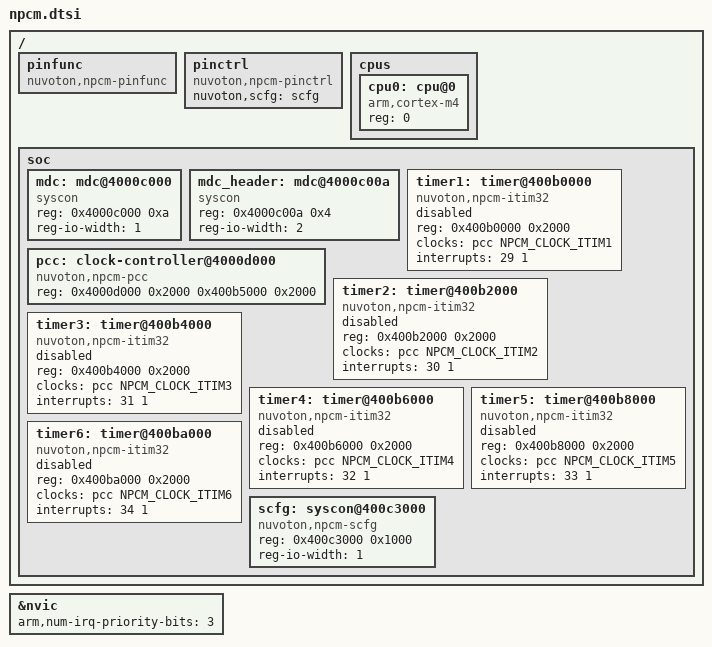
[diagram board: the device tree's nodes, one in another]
/*
 * Copyright (c) 2024 Nuvoton Technology Corporation.
 *
 * SPDX-License-Identifier: Apache-2.0
 */

#include <arm/armv7-m.dtsi>

/* Macros for device tree declarations of npcm soc family */
#include <zephyr/dt-bindings/clock/npcm_clock.h>
#include <freq.h>

/ {
	pinfunc: pinfunc {
		compatible = "nuvoton,npcm-pinfunc";
	};

	pinctrl: pinctrl {
		compatible = "nuvoton,npcm-pinctrl";
		nuvoton,scfg = <&scfg>;
	};

	cpus {
		#address-cells = <1>;
		#size-cells = <0>;

		cpu0: cpu@0 {
			compatible = "arm,cortex-m4";
			reg = <0>;
			device_type = "cpu";
		};
	};

	soc {
		mdc: mdc@4000c000 {
			compatible = "syscon";
			reg = <0x4000c000 0xa>;
			reg-io-width = <1>;
		};

		mdc_header: mdc@4000c00a {
			compatible = "syscon";
			reg = <0x4000c00a 0x4>;
			reg-io-width = <2>;
		};

		pcc: clock-controller@4000d000 {
			compatible = "nuvoton,npcm-pcc";
			/* First reg region is Power Management Controller */
			/* Second reg region is Core Domain Clock Generator */
			reg = <0x4000d000 0x2000
			       0x400b5000 0x2000>;
			/* Cells for clock id */
			#clock-cells = <1>;
			reg-names = "pmc", "cdcg";
		};

		timer1: timer@400b0000 {
			compatible = "nuvoton,npcm-itim32";
			reg = <0x400b0000 0x2000>;
			clocks = <&pcc NPCM_CLOCK_ITIM1>;
			interrupts = <29 1>;
			status = "disabled";
		};

		timer2: timer@400b2000 {
			compatible = "nuvoton,npcm-itim32";
			reg = <0x400b2000 0x2000>;
			clocks = <&pcc NPCM_CLOCK_ITIM2>;
			interrupts = <30 1>;
			status = "disabled";
		};

		timer3: timer@400b4000 {
			compatible = "nuvoton,npcm-itim32";
			reg = <0x400b4000 0x2000>;
			clocks = <&pcc NPCM_CLOCK_ITIM3>;
			interrupts = <31 1>;
			status = "disabled";
		};

		timer4: timer@400b6000 {
			compatible = "nuvoton,npcm-itim32";
			reg = <0x400b6000 0x2000>;
			clocks = <&pcc NPCM_CLOCK_ITIM4>;
			interrupts = <32 1>;
			status = "disabled";
		};

		timer5: timer@400b8000 {
			compatible = "nuvoton,npcm-itim32";
			reg = <0x400b8000 0x2000>;
			clocks = <&pcc NPCM_CLOCK_ITIM5>;
			interrupts = <33 1>;
			status = "disabled";
		};

		timer6: timer@400ba000 {
			compatible = "nuvoton,npcm-itim32";
			reg = <0x400ba000 0x2000>;
			clocks = <&pcc NPCM_CLOCK_ITIM6>;
			interrupts = <34 1>;
			status = "disabled";
		};

		scfg: syscon@400c3000 {
			compatible = "nuvoton,npcm-scfg", "syscon";
			/* System Configuration (SCFG) */
			reg = <0x400c3000 0x1000>;
			reg-io-width = <1>;
		};
	};
};

&nvic {
	arm,num-irq-priority-bits = <3>;
};
